# K1921VK01T register map
Vendor: NIIET; Series: K1921VKx; File version: 2.2
CPU: CM4 r0p1, little endian, MPU, FPU, 3 interrupt priority bits
Registers are 32-bit, read-write, reset 0x0 unless marked. A register's access mark holds for its fields unless they carry their own. Offsets are from the block's base; [hi:lo] are bit positions; {n}, {i} and the like mark numbered series.

## NT_TIMER0 — TIMER controller registers
Base 0xA0003000
Same registers: NT_TIMER1 0xA0004000, NT_TIMER2 0xA0005000
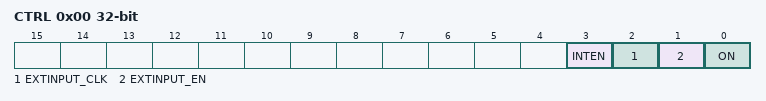
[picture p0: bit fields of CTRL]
0x00 CTRL — Control Timer register
  [3] INTEN — Enable Timer interrupt
  [2] EXTINPUT_CLK — Enable extern input clock
  [1] EXTINPUT_EN — Enable extern
  [0] ON — Enable Timer
0x04 VALUE — Current value timer register
0x08 RELOAD — Reload value timer register
0x0C INTSTATUS_INTCLEAR
  [0] INT — Timer interrupt flag

## NT_DMA — DMA controller registers
Base 0xA0006000
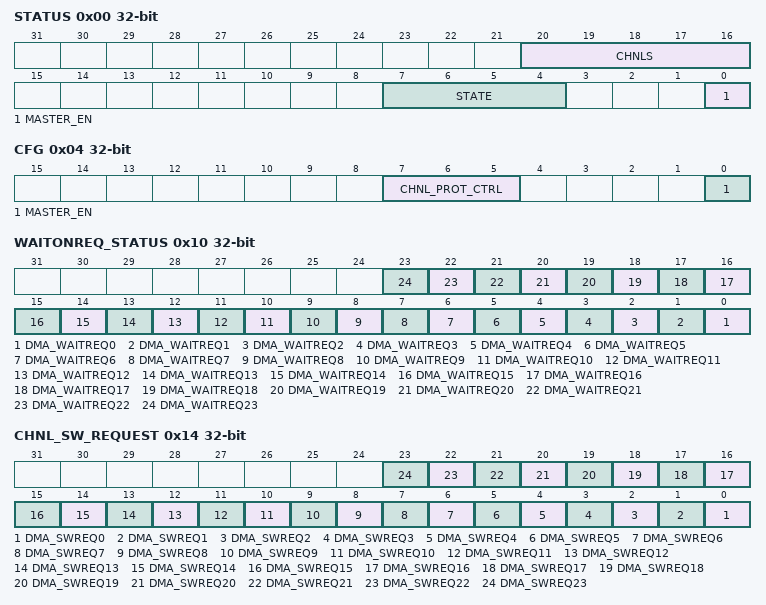
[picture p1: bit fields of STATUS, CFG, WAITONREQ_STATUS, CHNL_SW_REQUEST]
0x00 STATUS ro — Status DMA register
  [20:16] CHNLS — Number channel DMA (write: N-1)
  [7:4] STATE — State of DMA
    on read: 0=Free (At rest); 1=ReadConfigData (Reading the config data structure); 2=ReadSrcDataEndPtr (Reading sourse data end pointer); 3=ReadDstDataEndPtr (Reading destination data end pointer); 4=ReadSrcData (Reading source data); 5=WrireDstData (Writing data to the destination); 6=WaitReq (Waiting for a request); 7=WriteConfigData (Write config structure of the channel); 8=Pause (Suspended); 9=Done (Executed); 10=PeriphScatGath (mode "peripheral scather-gather")
  [0] MASTER_EN — Indicate enable DMA
0x04 CFG wo — Configurate DMA register
  [7:5] CHNL_PROT_CTRL — Enable control HPROT.1 for access indication with buffering
  [0] MASTER_EN — Enable DMA
0x08 CTRL_BASE_PTR — Base address register control data channels
  [31:10] CTRL_BASE_PTR — Pointer to base address of the primary structure of the control data
0x0C ALT_CTRL_BASE_PTR ro — Alternate base address register control data channels
  [31:0] ALT_CTRL_BASE_PTR — Base address of alternative control data channels
0x10 WAITONREQ_STATUS ro — DMA wait request status
  [n] DMA_WAITREQ{n} (n=0..23) — Returns the status of the DMA request signals
0x14 CHNL_SW_REQUEST wo — Register software process request DMA channels
  [n] DMA_SWREQ{n} (n=0..23) — Set software request on channel {n}
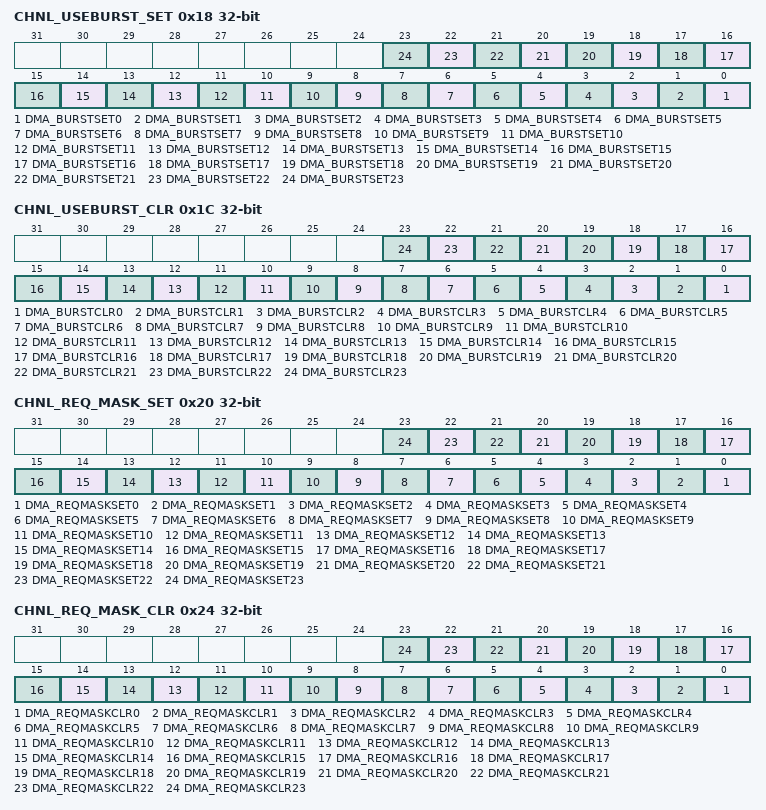
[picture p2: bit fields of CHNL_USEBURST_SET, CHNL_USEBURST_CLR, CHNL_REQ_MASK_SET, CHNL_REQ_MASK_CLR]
0x18 CHNL_USEBURST_SET — Register Set Packet Exchange DMA channels
  [n] DMA_BURSTSET{n} (n=0..23) — Returns the status of the DMA single request signals
0x1C CHNL_USEBURST_CLR wo — Register Clear Packet Exchange DMA channels
  [n] DMA_BURSTCLR{n} (n=0..23) — reserved
0x20 CHNL_REQ_MASK_SET — DMA request mask set
  [n] DMA_REQMASKSET{n} (n=0..23)
0x24 CHNL_REQ_MASK_CLR wo — DMA request mask clear
  [n] DMA_REQMASKCLR{n} (n=0..23)
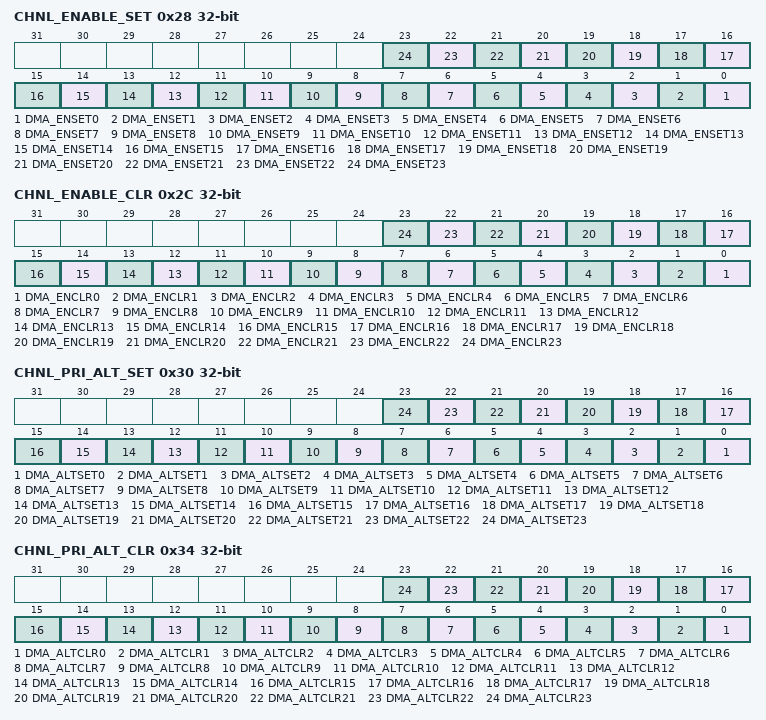
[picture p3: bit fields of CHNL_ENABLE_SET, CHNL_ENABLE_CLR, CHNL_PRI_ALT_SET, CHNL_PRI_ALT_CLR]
0x28 CHNL_ENABLE_SET — DMA channel enabled set
  [n] DMA_ENSET{n} (n=0..23) — Returns the status of dma_active[ ]
0x2C CHNL_ENABLE_CLR wo — DMA channel enabled clear
  [n] DMA_ENCLR{n} (n=0..23) — Enables you to set the dma_active[ ]
0x30 CHNL_PRI_ALT_SET — Register setting primary / alternate channel control data structure
  [n] DMA_ALTSET{n} (n=0..23) — Set primary / alternate channel control data structure
0x34 CHNL_PRI_ALT_CLR wo — Register clearing primary / alternate channel control data structure
  [n] DMA_ALTCLR{n} (n=0..23) — Clear primary / alternate channel control data structure
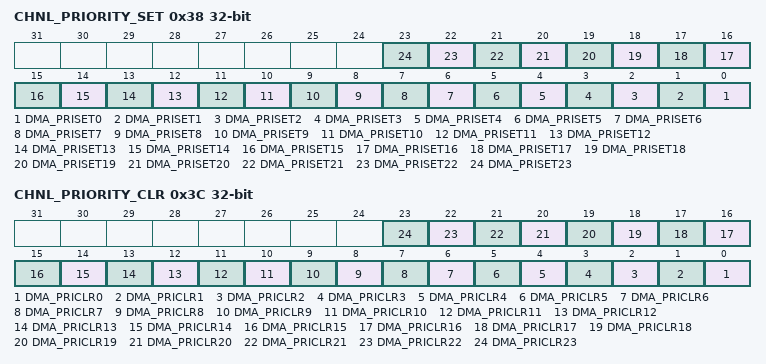
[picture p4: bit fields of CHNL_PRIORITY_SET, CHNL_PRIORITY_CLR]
0x38 CHNL_PRIORITY_SET — Register set the priority channel
  [n] DMA_PRISET{n} (n=0..23) — Set the priority channel{n}
0x3C CHNL_PRIORITY_CLR wo — Register clear the priority channel
  [n] DMA_PRICLR{n} (n=0..23) — Clear the priority channel{n}
0x4C ERR_CLR — Flag error clear register
  [0] ERR_CLR — Indicate Error on bus AHB-Lite / Clear flag error

## NT_CAP0 — CAP controller registers
Base 0xA0014000
Same registers: NT_CAP1 0xA0015000, NT_CAP2 0xA0016000, NT_CAP3 0xA0017000, NT_CAP4 0xA0018000, NT_CAP5 0xA0019000
0x00 TSCTR — TIMER register
  [31:0] VALUE
0x04 CTRPHS — Load Timer register
  [31:0] VALUE
{0x8+4i} CAP{i} (i=0..3) — Capture register {i}
  [31:0] VALUE
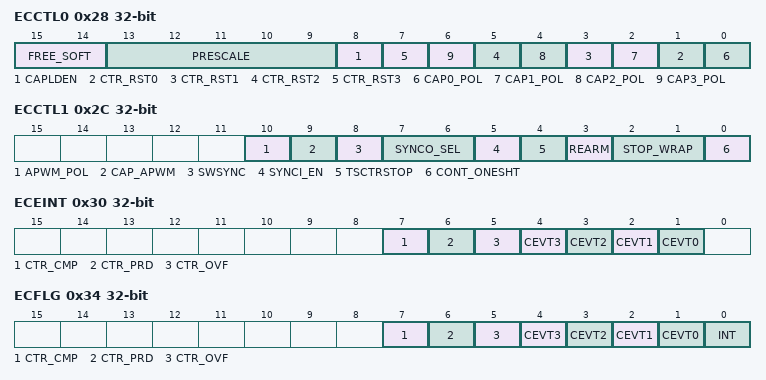
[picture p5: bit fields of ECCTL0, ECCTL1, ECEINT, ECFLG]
0x28 ECCTL0 — Register capture control 0
  [15:14] FREE_SOFT
    0=stop timer immedeatelly; 1=StopAtZero (stop timer when reach zero)
  [13:9] PRESCALE
  [8] CAPLDEN — enable capture
  [2n+1] CTR_RST{n} (n=0..3) — reset later event {n}
  [2n] CAP{n}_POL (n=0..3) — pos/negedge capture {n}
0x2C ECCTL1 — Register capture control 1
  [10] APWM_POL — High/low level APWM
  [9] CAP_APWM — Capture mode or APWM
  [8] SWSYNC — Timers synchr
  [7:6] SYNCO_SEL
    0=Bypass (sync in connected with sync out); 1=CTREqPrd (sync out generated when CTR = PRD); 2=Disable (sync out generate disabled)
  [5] SYNCI_EN — sync outer impulse
  [4] TSCTRSTOP — enable Timer
  [3] REARM — reset and enable controller, load reg capt
  [2:1] STOP_WRAP
  [0] CONT_ONESHT — Capture mode
0x30 ECEINT — Register interrupt mask
  [7] CTR_CMP — enable int CTR=CMP
  [6] CTR_PRD — enable int CTR=PRD
  [5] CTR_OVF — enable int CTR_OVF
  [n+1] CEVT{n} (n=0..3) — enable int CEVT{n}
0x34 ECFLG ro — Register interrupt status
  [7] CTR_CMP — Hap interrupt CTR=CMP
  [6] CTR_PRD — Hap interrupt CTR=PRD
  [5] CTR_OVF — Hap interrupt CTROVF
  [n+1] CEVT{n} (n=0..3) — Hap interrupt CEVT{n}
  [0] INT — indicate global interrupt
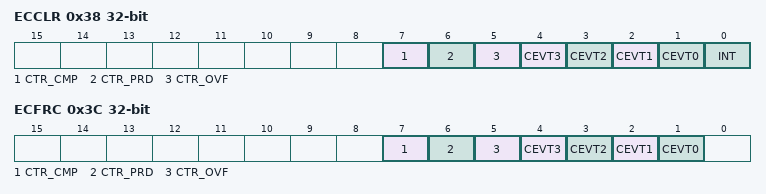
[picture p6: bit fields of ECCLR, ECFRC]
0x38 ECCLR — Register reset interrupt
  [7] CTR_CMP — reset intstatus
  [6] CTR_PRD — reset intstatus
  [5] CTR_OVF — reset intstatus
  [n+1] CEVT{n} (n=0..3) — reset intstatus
  [0] INT — reset global interrupt
0x3C ECFRC — Test register interrupt generation
  [7] CTR_CMP — gen test interrupt
  [6] CTR_PRD — gen test interrupt
  [5] CTR_OVF — gen test interrupt
  [n+1] CEVT{n} (n=0..3) — gen test interrupt
0x40 PEINT — Active interrupt status register
  [0] PEINT — active interrupt flag
